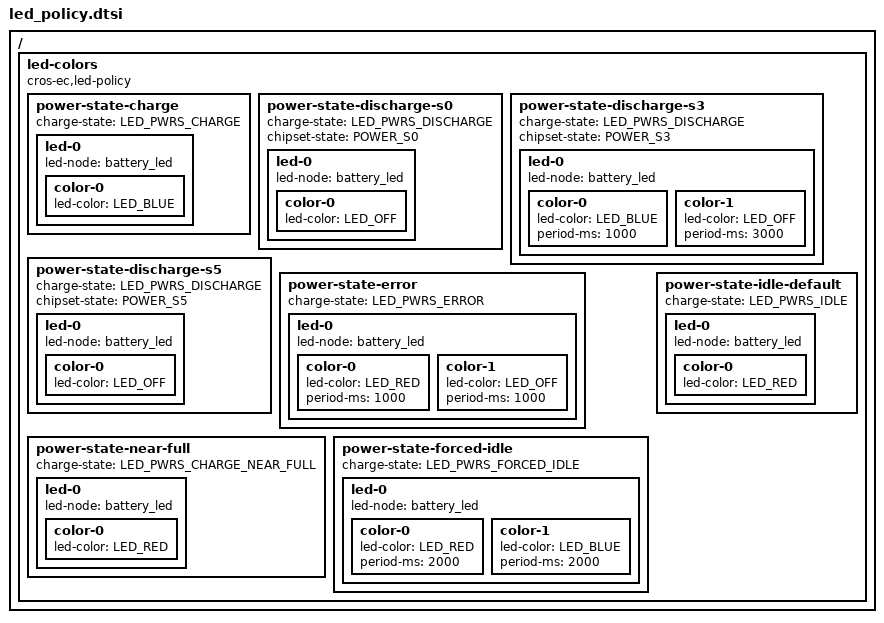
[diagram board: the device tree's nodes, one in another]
/* Copyright 2022 The ChromiumOS Authors
 * Use of this source code is governed by a BSD-style license that can be
 * found in the LICENSE file.
 */

/ {
	led-colors {
		compatible = "cros-ec,led-policy";

		power-state-charge {
			charge-state = "LED_PWRS_CHARGE";

			led-0 {
				led-node = <&battery_led>;

				color-0 {
					led-color = "LED_BLUE";
				};
			};
		};

		power-state-discharge-s0 {
			charge-state = "LED_PWRS_DISCHARGE";
			chipset-state = "POWER_S0";

			led-0 {
				led-node = <&battery_led>;

				color-0 {
					led-color = "LED_OFF";
				};
			};
		};

		power-state-discharge-s3 {
			charge-state = "LED_PWRS_DISCHARGE";
			chipset-state = "POWER_S3";

			led-0 {
				led-node = <&battery_led>;

				/* Blue 1 sec, off 3 sec */
				color-0 {
					led-color = "LED_BLUE";
					period-ms = <1000>;
				};
				color-1 {
					led-color = "LED_OFF";
					period-ms = <3000>;
				};
			};
		};

		power-state-discharge-s5 {
			charge-state = "LED_PWRS_DISCHARGE";
			chipset-state = "POWER_S5";

			led-0 {
				led-node = <&battery_led>;

				color-0 {
					led-color = "LED_OFF";
				};
			};
		};

		power-state-error {
			charge-state = "LED_PWRS_ERROR";

			led-0 {
				led-node = <&battery_led>;

				/* Red 1 sec, off 1 sec */
				color-0 {
					led-color = "LED_RED";
					period-ms = <1000>;
				};
				color-1 {
					led-color = "LED_OFF";
					period-ms = <1000>;
				};
			};
		};

		power-state-near-full {
			charge-state = "LED_PWRS_CHARGE_NEAR_FULL";

			led-0 {
				led-node = <&battery_led>;

				color-0 {
					led-color = "LED_RED";
				};
			};
		};

		power-state-forced-idle {
			charge-state = "LED_PWRS_FORCED_IDLE";

			led-0 {
				led-node = <&battery_led>;

				/* Red 2 sec, Blue 2 sec */
				color-0 {
					led-color = "LED_RED";
					period-ms = <2000>;
				};
				color-1 {
					led-color = "LED_BLUE";
					period-ms = <2000>;
				};
			};
		};

		power-state-idle-default {
			charge-state = "LED_PWRS_IDLE";

			led-0 {
				led-node = <&battery_led>;

				color-0 {
					led-color = "LED_RED";
				};
			};
		};
	};
};
